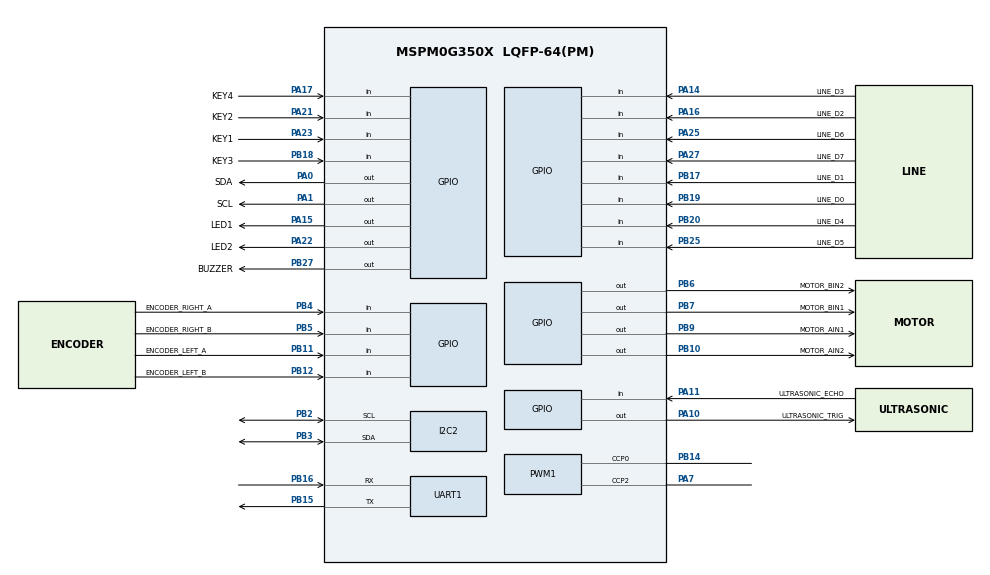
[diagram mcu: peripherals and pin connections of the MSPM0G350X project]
/**
 * @cliArgs --device "MSPM0G350X" --part "Default" --package "LQFP-64(PM)" --product "mspm0_sdk@2.11.00.07"
 * @versions {"tool":"1.26.2+4477"}
 */

/**
 * Import the modules used in this configuration.
 */
const GPIO   = scripting.addModule("/ti/driverlib/GPIO", {}, false);
const GPIO1  = GPIO.addInstance();
const GPIO2  = GPIO.addInstance();
const GPIO3  = GPIO.addInstance();
const GPIO4  = GPIO.addInstance();
const GPIO5  = GPIO.addInstance();
const GPIO6  = GPIO.addInstance();
const I2C    = scripting.addModule("/ti/driverlib/I2C", {}, false);
const I2C2   = I2C.addInstance();
const PWM    = scripting.addModule("/ti/driverlib/PWM", {}, false);
const PWM1   = PWM.addInstance();
const SYSCTL = scripting.addModule("/ti/driverlib/SYSCTL");
const TIMER  = scripting.addModule("/ti/driverlib/TIMER", {}, false);
const TIMER1 = TIMER.addInstance();
const UART   = scripting.addModule("/ti/driverlib/UART", {}, false);
const UART1  = UART.addInstance();

/**
 * Write custom configuration values to the imported modules.
 */
GPIO1.$name                         = "GPIO_MOTOR";
GPIO1.associatedPins.create(4);
GPIO1.associatedPins[0].$name       = "MOTOR_AIN1";
GPIO1.associatedPins[0].pin.$assign = "PB9";
GPIO1.associatedPins[1].$name       = "MOTOR_AIN2";
GPIO1.associatedPins[1].pin.$assign = "PB10";
GPIO1.associatedPins[2].$name       = "MOTOR_BIN1";
GPIO1.associatedPins[2].pin.$assign = "PB7";
GPIO1.associatedPins[3].$name       = "MOTOR_BIN2";
GPIO1.associatedPins[3].pin.$assign = "PB6";

const Board = scripting.addModule("/ti/driverlib/Board", {}, false);

GPIO2.$name                              = "GPIO_LINE";
GPIO2.associatedPins.create(8);
GPIO2.associatedPins[0].$name            = "LINE_D0";
GPIO2.associatedPins[0].direction        = "INPUT";
GPIO2.associatedPins[0].internalResistor = "PULL_UP";
GPIO2.associatedPins[0].pin.$assign      = "PB19";
GPIO2.associatedPins[1].$name            = "LINE_D1";
GPIO2.associatedPins[1].direction        = "INPUT";
GPIO2.associatedPins[1].internalResistor = "PULL_UP";
GPIO2.associatedPins[1].pin.$assign      = "PB17";
GPIO2.associatedPins[2].$name            = "LINE_D2";
GPIO2.associatedPins[2].direction        = "INPUT";
GPIO2.associatedPins[2].internalResistor = "PULL_UP";
GPIO2.associatedPins[2].pin.$assign      = "PA16";
GPIO2.associatedPins[3].$name            = "LINE_D3";
GPIO2.associatedPins[3].direction        = "INPUT";
GPIO2.associatedPins[3].internalResistor = "PULL_UP";
GPIO2.associatedPins[3].pin.$assign      = "PA14";
GPIO2.associatedPins[4].$name            = "LINE_D4";
GPIO2.associatedPins[4].direction        = "INPUT";
GPIO2.associatedPins[4].internalResistor = "PULL_UP";
GPIO2.associatedPins[4].pin.$assign      = "PB20";
GPIO2.associatedPins[5].$name            = "LINE_D5";
GPIO2.associatedPins[5].direction        = "INPUT";
GPIO2.associatedPins[5].internalResistor = "PULL_UP";
GPIO2.associatedPins[5].pin.$assign      = "PB25";
GPIO2.associatedPins[6].$name            = "LINE_D6";
GPIO2.associatedPins[6].direction        = "INPUT";
GPIO2.associatedPins[6].internalResistor = "PULL_UP";
GPIO2.associatedPins[6].pin.$assign      = "PA25";
GPIO2.associatedPins[7].$name            = "LINE_D7";
GPIO2.associatedPins[7].direction        = "INPUT";
GPIO2.associatedPins[7].internalResistor = "PULL_UP";
GPIO2.associatedPins[7].pin.$assign      = "PA27";

GPIO3.$name                              = "GPIO_ENCODER";
GPIO3.associatedPins.create(4);
GPIO3.associatedPins[0].$name            = "ENCODER_LEFT_A";
GPIO3.associatedPins[0].direction        = "INPUT";
GPIO3.associatedPins[0].internalResistor = "PULL_UP";
GPIO3.associatedPins[0].interruptEn      = true;
GPIO3.associatedPins[0].polarity         = "RISE_FALL";
GPIO3.associatedPins[0].pin.$assign      = "PB11";
GPIO3.associatedPins[1].$name            = "ENCODER_LEFT_B";
GPIO3.associatedPins[1].direction        = "INPUT";
GPIO3.associatedPins[1].internalResistor = "PULL_UP";
GPIO3.associatedPins[1].pin.$assign      = "PB12";
GPIO3.associatedPins[2].$name            = "ENCODER_RIGHT_A";
GPIO3.associatedPins[2].direction        = "INPUT";
GPIO3.associatedPins[2].internalResistor = "PULL_UP";
GPIO3.associatedPins[2].interruptEn      = true;
GPIO3.associatedPins[2].polarity         = "RISE_FALL";
GPIO3.associatedPins[2].pin.$assign      = "PB4";
GPIO3.associatedPins[3].$name            = "ENCODER_RIGHT_B";
GPIO3.associatedPins[3].direction        = "INPUT";
GPIO3.associatedPins[3].internalResistor = "PULL_UP";
GPIO3.associatedPins[3].pin.$assign      = "PB5";

GPIO4.$name                         = "GPIO_UI";
GPIO4.associatedPins.create(3);
GPIO4.associatedPins[0].$name       = "BUZZER";
GPIO4.associatedPins[0].pin.$assign = "PB27";
GPIO4.associatedPins[1].$name       = "ULTRASONIC_TRIG";
GPIO4.associatedPins[1].pin.$assign = "PA10";
GPIO4.associatedPins[2].$name       = "ULTRASONIC_ECHO";
GPIO4.associatedPins[2].direction   = "INPUT";
GPIO4.associatedPins[2].pin.$assign = "PA11";

GPIO5.$name                              = "GPIO_KEYS";
GPIO5.associatedPins.create(4);
GPIO5.associatedPins[0].$name            = "KEY1";
GPIO5.associatedPins[0].direction        = "INPUT";
GPIO5.associatedPins[0].internalResistor = "PULL_UP";
GPIO5.associatedPins[0].pin.$assign      = "PA23";
GPIO5.associatedPins[1].$name            = "KEY2";
GPIO5.associatedPins[1].direction        = "INPUT";
GPIO5.associatedPins[1].internalResistor = "PULL_UP";
GPIO5.associatedPins[1].pin.$assign      = "PA21";
GPIO5.associatedPins[2].$name            = "KEY3";
GPIO5.associatedPins[2].direction        = "INPUT";
GPIO5.associatedPins[2].internalResistor = "PULL_UP";
GPIO5.associatedPins[2].pin.$assign      = "PB18";
GPIO5.associatedPins[3].$name            = "KEY4";
GPIO5.associatedPins[3].direction        = "INPUT";
GPIO5.associatedPins[3].internalResistor = "PULL_UP";
GPIO5.associatedPins[3].pin.$assign      = "PA17";

GPIO6.$name                         = "GPIO_LED";
GPIO6.associatedPins.create(2);
GPIO6.associatedPins[0].$name       = "LED1";
GPIO6.associatedPins[0].pin.$assign = "PA15";
GPIO6.associatedPins[1].$name       = "LED2";
GPIO6.associatedPins[1].pin.$assign = "PA22";

const GPIO7 = GPIO.addInstance();
GPIO7.$name                         = "GPIO_OLED";
GPIO7.associatedPins.create(2);
GPIO7.associatedPins[0].$name       = "SCL";
GPIO7.associatedPins[0].pin.$assign = "PA1";
GPIO7.associatedPins[1].$name       = "SDA";
GPIO7.associatedPins[1].pin.$assign = "PA0";

I2C2.$name                             = "I2C_MPU6050";
I2C2.basicEnableController             = true;
I2C2.basicControllerBusSpeed           = 400000;
I2C2.peripheral.$assign                = "I2C1";
I2C2.peripheral.sdaPin.$assign         = "PB3";
I2C2.peripheral.sclPin.$assign         = "PB2";
I2C2.sdaPinConfig.$name                = "ti_driverlib_gpio_GPIOPinGeneric2";
I2C2.sdaPinConfig.hideOutputInversion  = scripting.forceWrite(false);
I2C2.sdaPinConfig.onlyInternalResistor = scripting.forceWrite(false);
I2C2.sdaPinConfig.passedPeripheralType = scripting.forceWrite("Digital");
I2C2.sclPinConfig.$name                = "ti_driverlib_gpio_GPIOPinGeneric3";
I2C2.sclPinConfig.hideOutputInversion  = scripting.forceWrite(false);
I2C2.sclPinConfig.onlyInternalResistor = scripting.forceWrite(false);
I2C2.sclPinConfig.passedPeripheralType = scripting.forceWrite("Digital");

PWM1.$name                              = "PWM_MOTOR";
PWM1.timerCount                         = 1600;
PWM1.pwmMode                            = "EDGE_ALIGN_UP";
PWM1.ccIndex                            = [0,2];
PWM1.PWM_CHANNEL_0.$name                = "MOTOR_A_PWM";
PWM1.ccp0PinConfig.$name                = "ti_driverlib_gpio_GPIOPinGeneric4";
PWM1.ccp0PinConfig.direction            = scripting.forceWrite("OUTPUT");
PWM1.ccp0PinConfig.hideOutputInversion  = scripting.forceWrite(false);
PWM1.ccp0PinConfig.onlyInternalResistor = scripting.forceWrite(false);
PWM1.ccp0PinConfig.passedPeripheralType = scripting.forceWrite("Digital");
PWM1.peripheral.$assign                 = "TIMA0";
PWM1.peripheral.ccp0Pin.$assign         = "PB14";
PWM1.peripheral.ccp2Pin.$assign         = "PA7";
PWM1.PWM_CHANNEL_2.$name                = "MOTOR_B_PWM";
PWM1.ccp2PinConfig.$name                = "ti_driverlib_gpio_GPIOPinGeneric5";

SYSCTL.forceDefaultClkConfig = true;
SYSCTL.clockTreeEn           = true;

TIMER1.$name              = "TIMER_CONTROL";
TIMER1.interrupts         = ["ZERO"];
TIMER1.timerClkSrc        = "LFCLK";
TIMER1.timerMode          = "PERIODIC";
TIMER1.timerPeriod        = "6.667 ms";
TIMER1.peripheral.$assign = "TIMG0";

UART1.$name                            = "UART_DEBUG";
UART1.targetBaudRate                   = 115200;
UART1.peripheral.$assign               = "UART2";
UART1.peripheral.rxPin.$assign         = "PB16";
UART1.peripheral.txPin.$assign         = "PB15";
UART1.txPinConfig.$name                = "ti_driverlib_gpio_GPIOPinGeneric6";
UART1.txPinConfig.direction            = scripting.forceWrite("OUTPUT");
UART1.txPinConfig.hideOutputInversion  = scripting.forceWrite(false);
UART1.txPinConfig.onlyInternalResistor = scripting.forceWrite(false);
UART1.txPinConfig.passedPeripheralType = scripting.forceWrite("Digital");
UART1.rxPinConfig.$name                = "ti_driverlib_gpio_GPIOPinGeneric7";
UART1.rxPinConfig.hideOutputInversion  = scripting.forceWrite(false);
UART1.rxPinConfig.onlyInternalResistor = scripting.forceWrite(false);
UART1.rxPinConfig.passedPeripheralType = scripting.forceWrite("Digital");

/**
 * Pinmux solution for unlocked pins/peripherals. This ensures that minor changes to the automatic solver in a future
 * version of the tool will not impact the pinmux you originally saw.  These lines can be completely deleted in order to
 * re-solve from scratch.
 */
Board.peripheral.$suggestSolution          = "DEBUGSS";
Board.peripheral.swclkPin.$suggestSolution = "PA20";
Board.peripheral.swdioPin.$suggestSolution = "PA19";
